# APM32F411 register map
Vendor: Geehy; File version: 2024.11.05
CPU: CM4 r1p0, little endian, 3 interrupt priority bits
Registers are 32-bit, read-write, reset 0x0 unless marked. A register's access mark holds for its fields unless they carry their own. Offsets are from the block's base; [hi:lo] are bit positions; {n}, {i} and the like mark numbered series; 'fields as' and 'values as' point back to an identical list.

## NVIC — Nested Vectored Interrupt Controller
Base 0xE000E100
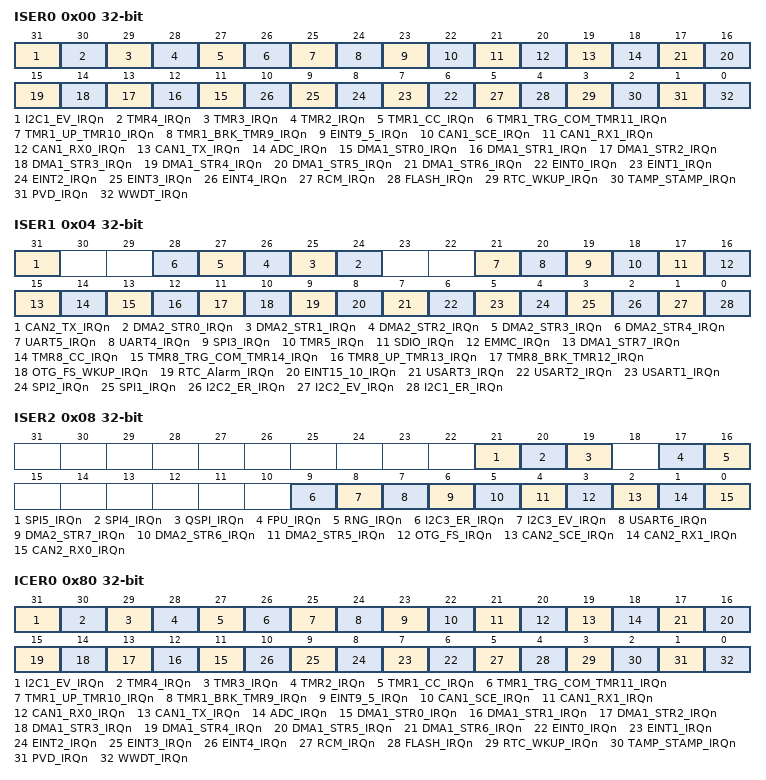
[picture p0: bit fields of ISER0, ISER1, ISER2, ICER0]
0x00 ISER0 — Interrupt Set-Enable Register
  [31] I2C1_EV_IRQn — I2C1 Event Interrupt
  [30] TMR4_IRQn — TMR4 global Interrupt
  [29] TMR3_IRQn — TMR3 global Interrupt
  [28] TMR2_IRQn — TMR2 global Interrupt
  [27] TMR1_CC_IRQn — TMR1 Capture/Compare Interrupt
  [26] TMR1_TRG_COM_TMR11_IRQn — TMR1 Trigger AND TMR11 global Interrupt
  [25] TMR1_UP_TMR10_IRQn — TMR1 Update AND TMR10 global Interrupt
  [24] TMR1_BRK_TMR9_IRQn — TMR1 Break AND TMR9 global Interrupt
  [23] EINT9_5_IRQn — External Lines [9:5] Interrupt
  [22] CAN1_SCE_IRQn — CAN1 SCE Interrupt
  [21] CAN1_RX1_IRQn — CAN1 RX1 Interrupt
  [20] CAN1_RX0_IRQn — CAN1 RX0 Interrupt
  [19] CAN1_TX_IRQn — CAN1 TX Interrupt
  [18] ADC_IRQn — ADC Interrupt
  [n+11] DMA1_STR{n}_IRQn (n=0..6) — DMA1 Stream{n} global Interrupt
  [n+6] EINT{n}_IRQn (n=0..4) — External Line{n} Interrupt
  [5] RCM_IRQn — RCM global Interrupt
  [4] FLASH_IRQn — FLASH global Interrupt
  [3] RTC_WKUP_IRQn — RTC Wakeup Interrupt
  [2] TAMP_STAMP_IRQn — Tamper/TimeStamp Interrupt
  [1] PVD_IRQn — PVD through EINT Line detection Interrupt
  [0] WWDT_IRQn — Window WatchDog Interrupt
0x04 ISER1 — Interrupt Set-Enable Register
  [31] CAN2_TX_IRQn — CAN2 TX Interrupt
  [n+24] DMA2_STR{n}_IRQn (n=0..4) — DMA2 Stream{n} global Interrupt
  [21] UART5_IRQn — UART5 global Interrupt
  [20] UART4_IRQn — UART4 global Interrupt
  [19] SPI3_IRQn — SPI3 global Interrupt
  [18] TMR5_IRQn — TMR5 global Interrupt
  [17] SDIO_IRQn — SDIO global Interrupt
  [16] EMMC_IRQn — FSMC/EMMC global Interrupt
  [15] DMA1_STR7_IRQn — DMA1 Stream7 Interrupt
  [14] TMR8_CC_IRQn — TMR8 Capture Compare Interrupt
  [13] TMR8_TRG_COM_TMR14_IRQn — TMR8 Trigger/Commutation AND TMR14 global Interrupt
  [12] TMR8_UP_TMR13_IRQn — TMR8 Update AND TMR13 global Interrupt
  [11] TMR8_BRK_TMR12_IRQn — TMR8 Break AND TMR12 global Interrupt
  [10] OTG_FS_WKUP_IRQn — OTG_FS Wakeup through EINT line Interrupt
  [9] RTC_Alarm_IRQn — RTC Alarm (A and B) through EINT Line Interrupt
  [8] EINT15_10_IRQn — External Line[15:10] Interrupts Enable
  [7] USART3_IRQn — USART3 global Interrupt
  [6] USART2_IRQn — USART2 global Interrupt
  [5] USART1_IRQn — USART1 global Interrupt
  [4] SPI2_IRQn — SPI2 global Interrupt
  [3] SPI1_IRQn — SPI1 global Interrupt
  [2] I2C2_ER_IRQn — I2C2 Error Interrupt
  [1] I2C2_EV_IRQn — I2C2 Event Interrupt
  [0] I2C1_ER_IRQn — I2C1 Error Interrupt
0x08 ISER2 — Interrupt Set-Enable Register
  [21] SPI5_IRQn — SPI5 global Interrupt
  [20] SPI4_IRQn — SPI4 global Interrupt
  [19] QSPI_IRQn — QSPI global Interrupt
  [17] FPU_IRQn — FPU global Interrupt
  [16] RNG_IRQn — RNG global Interrupt
  [9] I2C3_ER_IRQn — I2C3 error Interrupt
  [8] I2C3_EV_IRQn — I2C3 event Interrupt
  [7] USART6_IRQn — USART6 global Interrupt
  [6] DMA2_STR7_IRQn — DMA2 Stream7 global Interrupt
  [5] DMA2_STR6_IRQn — DMA2 Stream6 global Interrupt
  [4] DMA2_STR5_IRQn — DMA2 Stream5 global Interrupt
  [3] OTG_FS_IRQn — OTG_FS global Interrupt
  [2] CAN2_SCE_IRQn — CAN2 SCE Interrupt
  [1] CAN2_RX1_IRQn — CAN2 RX1 Interrupt
  [0] CAN2_RX0_IRQn — CAN2 RX0 Interrupt
0x80 ICER0 — Interrupt Clear-Enable Register
  fields as ISER0
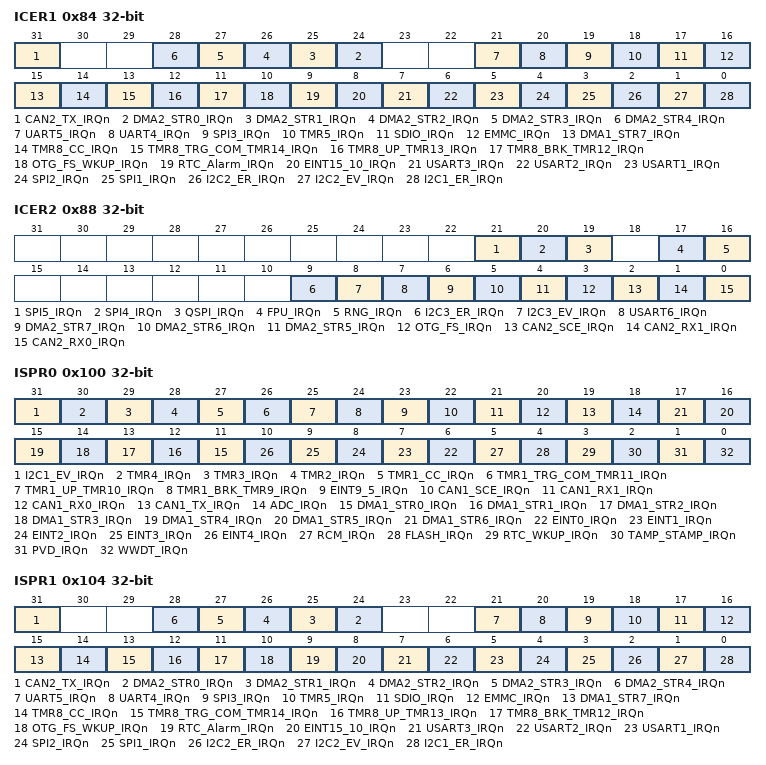
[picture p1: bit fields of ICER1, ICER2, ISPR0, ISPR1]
0x84 ICER1 — Interrupt Clear-Enable Register
  fields as ISER1
0x88 ICER2 — Interrupt Clear-Enable Register
  fields as ISER2
0x100 ISPR0 — Interrupt Set-Pending Register
  fields as ISER0
0x104 ISPR1 — Interrupt Set-Pending Register
  fields as ISER1
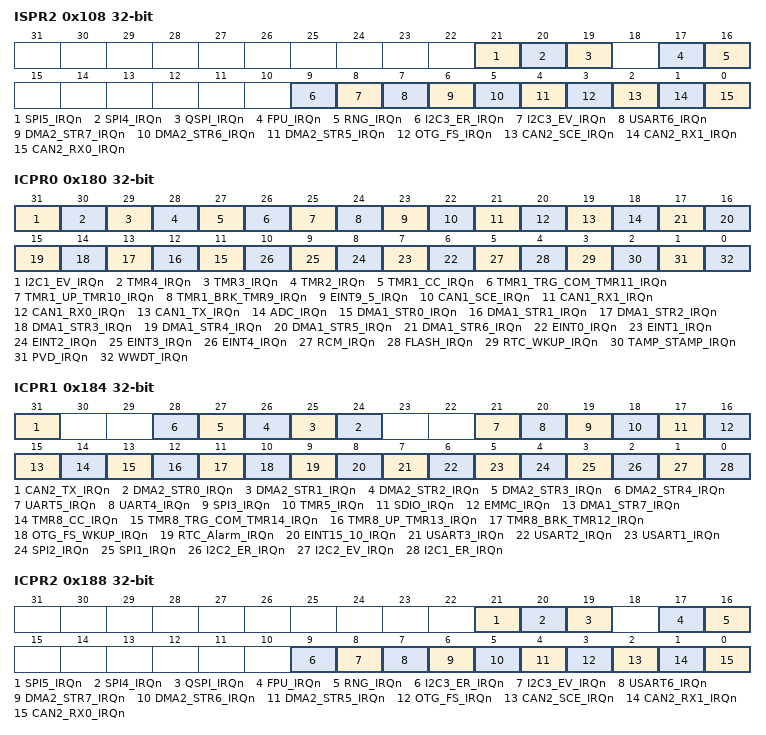
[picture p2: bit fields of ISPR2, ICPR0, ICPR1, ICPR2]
0x108 ISPR2 — Interrupt Set-Pending Register
  fields as ISER2
0x180 ICPR0 — Interrupt Clear-Pending Register
  fields as ISER0
0x184 ICPR1 — Interrupt Clear-Pending Register
  fields as ISER1
0x188 ICPR2 — Interrupt Clear-Pending Register
  fields as ISER2
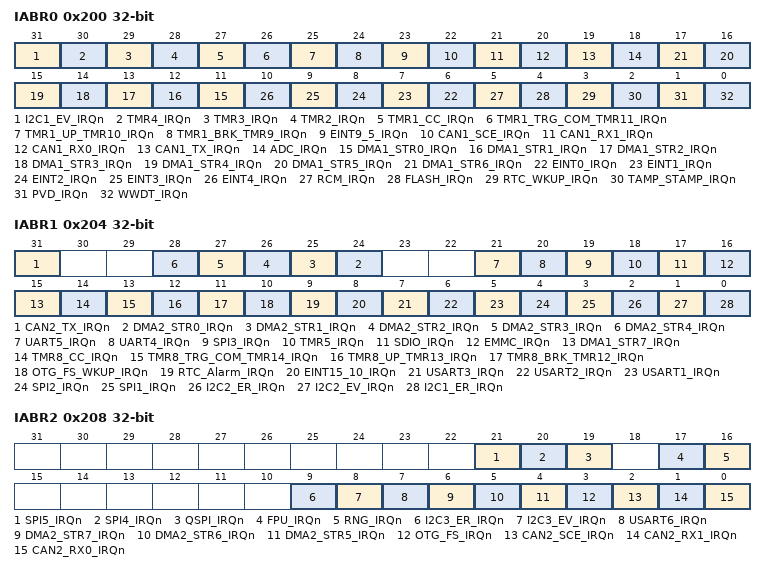
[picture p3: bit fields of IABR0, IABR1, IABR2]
0x200 IABR0 ro — Interrupt Active Bit Register
  fields as ISER0
0x204 IABR1 ro — Interrupt Active Bit Register
  fields as ISER1
0x208 IABR2 ro — Interrupt Active Bit Register
  fields as ISER2
{0x300+i} IPR{i} (i=0..79) 8-bit reset not defined — Interrupt Priority Register
  [7:4] PRI — Priority Bits
